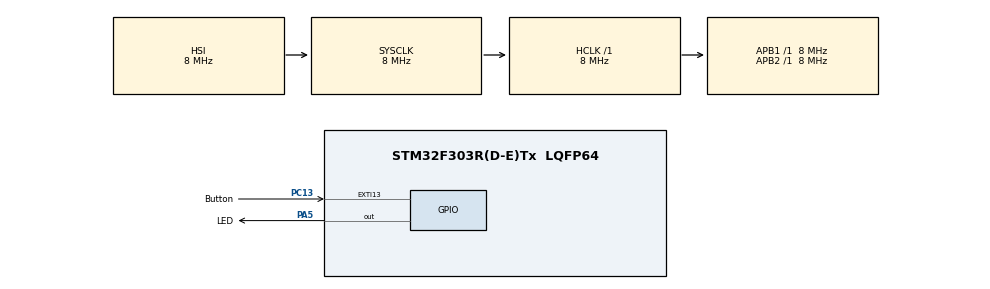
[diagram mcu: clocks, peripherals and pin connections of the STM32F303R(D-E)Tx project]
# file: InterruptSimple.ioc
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Mcu.Family=STM32F3
Mcu.Name=STM32F303R(D-E)Tx
Mcu.Package=LQFP64
NVIC.EXTI15_10_IRQn=true\:0\:0\:false\:false\:true\:true\:true\:true
NVIC.PriorityGroup=NVIC_PRIORITYGROUP_4
PA13.Mode=Serial_Wire
PA13.Signal=SYS_JTMS-SWDIO
PA14.Mode=Serial_Wire
PA14.Signal=SYS_JTCK-SWCLK
PA5.GPIO_Label=LED
PA5.Signal=GPIO_Output
PC13.GPIO_Label=Button
PC13.GPIO_ModeDefaultEXTI=GPIO_MODE_IT_FALLING
PC13.GPIO_PuPd=GPIO_PULLUP
PC13.Signal=GPXTI13
ProjectManager.HeapSize=0x200
ProjectManager.StackSize=0x400
ProjectManager.TargetToolchain=STM32CubeIDE
RCC.AHBFreq_Value=8000000
RCC.APB1Freq_Value=8000000
RCC.APB2Freq_Value=8000000
RCC.CortexFreq_Value=8000000
RCC.HSE_VALUE=8000000
RCC.HSI_VALUE=8000000
RCC.LSE_VALUE=32768
RCC.SYSCLKFreq_VALUE=8000000
RCC.USBFreq_Value=16000000
board=custom

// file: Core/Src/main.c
/* USER CODE BEGIN Header */
/**
  ******************************************************************************
  * @file           : main.c
  * @brief          : Main program body
  ******************************************************************************
  * @attention
  *
  * Copyright (c) 2023 STMicroelectronics.
  * All rights reserved.
  *
  * This software is licensed under terms that can be found in the LICENSE file
  * in the root directory of this software component.
  * If no LICENSE file comes with this software, it is provided AS-IS.
  *
  ******************************************************************************
  */
/* USER CODE END Header */
#include "main.h"

void SystemClock_Config(void);
static void MX_GPIO_Init(void);

/* USER CODE BEGIN 0 */
void HAL_GPIO_EXTI_Callback(uint16_t GPIO_Pin)
{
  /* Prevent unused argument(s) compilation warning */
  if (EXTI->PR & (1<<13)) EXTI->PR |= (1<<13);
  HAL_GPIO_TogglePin(GPIOA, LED_Pin);
  /* NOTE: This function should not be modified, when the callback is needed,
           the HAL_GPIO_EXTI_Callback could be implemented in the user file
   */
}
/* USER CODE END 0 */

int main(void)
{

  /* MCU Configuration--------------------------------------------------------*/

  /* Reset of all peripherals, Initializes the Flash interface and the Systick. */
  HAL_Init();

  /* Configure the system clock */
  SystemClock_Config();

  /* Initialize all configured peripherals */
  MX_GPIO_Init();

  /* Infinite loop */
  while (1)
  {

  }
}

void SystemClock_Config(void)
{
  RCC_OscInitTypeDef RCC_OscInitStruct = {0};
  RCC_ClkInitTypeDef RCC_ClkInitStruct = {0};

  /** Initializes the RCC Oscillators according to the specified parameters
  * in the RCC_OscInitTypeDef structure.
  */
  RCC_OscInitStruct.OscillatorType = RCC_OSCILLATORTYPE_HSI;
  RCC_OscInitStruct.HSIState = RCC_HSI_ON;
  RCC_OscInitStruct.HSICalibrationValue = RCC_HSICALIBRATION_DEFAULT;
  RCC_OscInitStruct.PLL.PLLState = RCC_PLL_NONE;
  if (HAL_RCC_OscConfig(&RCC_OscInitStruct) != HAL_OK)
  {
    Error_Handler();
  }

  /** Initializes the CPU, AHB and APB buses clocks
  */
  RCC_ClkInitStruct.ClockType = RCC_CLOCKTYPE_HCLK|RCC_CLOCKTYPE_SYSCLK
                              |RCC_CLOCKTYPE_PCLK1|RCC_CLOCKTYPE_PCLK2;
  RCC_ClkInitStruct.SYSCLKSource = RCC_SYSCLKSOURCE_HSI;
  RCC_ClkInitStruct.AHBCLKDivider = RCC_SYSCLK_DIV1;
  RCC_ClkInitStruct.APB1CLKDivider = RCC_HCLK_DIV1;
  RCC_ClkInitStruct.APB2CLKDivider = RCC_HCLK_DIV1;

  if (HAL_RCC_ClockConfig(&RCC_ClkInitStruct, FLASH_LATENCY_0) != HAL_OK)
  {
    Error_Handler();
  }
}

static void MX_GPIO_Init(void)
{
  GPIO_InitTypeDef GPIO_InitStruct = {0};

  /* GPIO Ports Clock Enable */
  __HAL_RCC_GPIOC_CLK_ENABLE();
  __HAL_RCC_GPIOA_CLK_ENABLE();

  /*Configure GPIO pin Output Level */
  HAL_GPIO_WritePin(LED_GPIO_Port, LED_Pin, GPIO_PIN_RESET);

  /*Configure GPIO pin : Button_Pin */
  GPIO_InitStruct.Pin = Button_Pin;
  GPIO_InitStruct.Mode = GPIO_MODE_IT_FALLING;
  GPIO_InitStruct.Pull = GPIO_PULLUP;
  HAL_GPIO_Init(Button_GPIO_Port, &GPIO_InitStruct);

  /*Configure GPIO pin : LED_Pin */
  GPIO_InitStruct.Pin = LED_Pin;
  GPIO_InitStruct.Mode = GPIO_MODE_OUTPUT_PP;
  GPIO_InitStruct.Pull = GPIO_NOPULL;
  GPIO_InitStruct.Speed = GPIO_SPEED_FREQ_LOW;
  HAL_GPIO_Init(LED_GPIO_Port, &GPIO_InitStruct);

  /* EXTI interrupt init*/
  HAL_NVIC_SetPriority(EXTI15_10_IRQn, 0, 0);
  HAL_NVIC_EnableIRQ(EXTI15_10_IRQn);

/* USER CODE BEGIN MX_GPIO_Init_2 */
  RCC->APB2ENR |= (0x1<0);
  // Enable SYSCFG bits in SYSCFG_EXTICR3
  // for PortC (0010)
  SYSCFG-> EXTICR[3]  &= ~(0xF<<4);
  // reset that slot first
  SYSCFG-> EXTICR[3]  |= (0x2<<4);
  // set as port C

  EXTI-> IMR |= (1<<13) ; // disable the MSAK for GPIO 13
  EXTI->FTSR |= (1<<1); // so we chose Falling edge from 1->0
  EXTI-> RTSR &=~(1<<1); // reset rising edge
  __set_BASEPRI(2);
  NVIC_SetPriority(EXTI15_10_IRQn,0); // OR
  NVIC_EnableIRQ(EXTI15_10_IRQn);
  __enable_irq();
  /* USER CODE END MX_GPIO_Init_2 */
}

void Error_Handler(void)
{
  __disable_irq();
  while (1)
  {
  }
}
